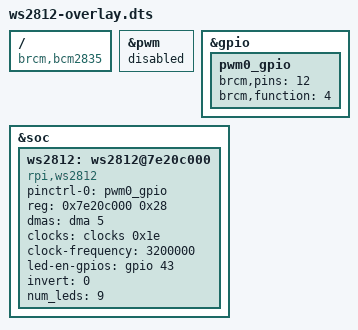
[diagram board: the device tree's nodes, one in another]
/dts-v1/;
/plugin/;

/ {
  compatible = "brcm,bcm2835";

  // disable pwm
  fragment@0 {
    target = <&pwm>;
    __overlay__ {
      status = "disabled";
    };
  };

  fragment@1 {
    target = <&gpio>;
    __overlay__ {
      pwm0_gpio: pwm0_gpio {
        brcm,pins=<12>;
        brcm,function=<4>;
      };
    };
  };

  fragment@2 {
    target = <&soc>;
    __overlay__ {

      #address-cells = <1>;
      #size-cells = <1>;

      ws2812: ws2812@7e20c000 {
        compatible = "rpi,ws2812";
        pinctrl-names = "default";
        pinctrl-0 = <&pwm0_gpio>;
        reg = <0x7e20c000 0x28>; /* PWM */
        dmas = <&dma 5>;
        dma-names = "pwm_dma";
        clocks = <&clocks 0x1e>;
        clock-frequency=<3200000>;
        led-en-gpios = <&gpio 43 0>;

        invert = <0>;
        num_leds = <9>;

        status = "okay";

      };
    };
  };

  __overrides__ {
    invert =        <&ws2812>,"invert:0";
    num_leds =      <&ws2812>,"num_leds:0";
    enable_gpio =   <&ws2812>,"led_en_gpios:4";
    gpio12      =   <&pwm0_gpio>,"brcm,pins:0=12",
                    <&pwm0_gpio>,"brcm,function:0=4";
    gpio18      =   <&pwm0_gpio>,"brcm,pins:0=18",
                    <&pwm0_gpio>,"brcm,function:0=2";
    gpio52      =   <&pwm0_gpio>,"brcm,pins:0=52",
                    <&pwm0_gpio>,"brcm,function:0=5";
  };
};
